# MIMXRT1061 register map
Vendor: nxp.com; File version: 1.0
CPU: CM7 r0p1, little endian, MPU, FPU, VTOR, 4 interrupt priority bits
Registers are 32-bit, read-write, reset 0x0 unless marked. A register's access mark holds for its fields unless they carry their own. Offsets are from the block's base; [hi:lo] are bit positions; {n}, {i} and the like mark numbered series; 'fields as' and 'values as' point back to an identical list.

## GPT1 — GPT
Base 0x401EC000
Same registers: GPT2 0x401F0000
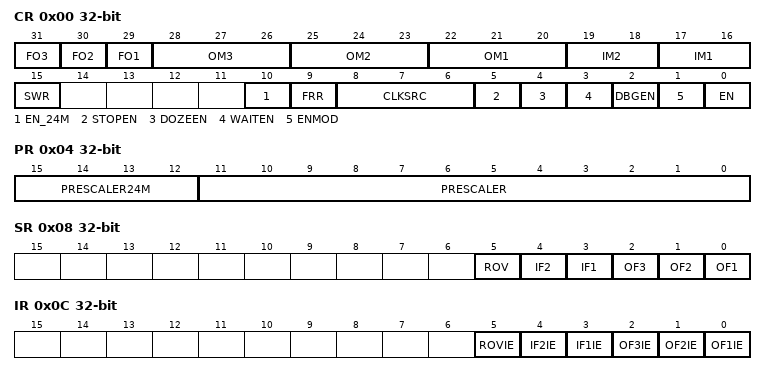
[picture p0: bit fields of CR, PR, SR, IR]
0x00 CR — GPT Control Register
  [31] FO3 — Force Output Compare for Channel 3
    0=NO_FORCE (No effect); 1=FORCE (Trigger the programmed response on the pin)
  [30] FO2 — Force Output Compare for Channel 2
    values as FO3
  [29] FO1 — Force Output Compare for Channel 1
    values as FO3
  [28:26] OM3 — Output Compare Operating Mode for Channel 3
    0=DISABLED (Output disabled. No response on pin.); 1=TOGGLE (Toggle output pin); 2=CLEAR (Clear output pin); 3=SET (Set output pin); 0b1xx=PULSE (Generate a low pulse that is one input clock cycle wide on the output pin. When OMn is first programmed as 1xx, the output pin is set to one immediately on the next input clock (if it was not one already). "Input clock" here refers to the clock selected by the CLKSRC field of this register.)
  [25:23] OM2 — Output Compare Operating Mode for Channel 2
    values as OM3
  [22:20] OM1 — Output Compare Operating Mode for Channel 1
    values as OM3
  [19:18] IM2 — Input Capture Operating Mode for Channel 2
    0=DISABLED (Capture disabled); 1=RISING (Capture on rising edge only); 2=FALLING (Capture on falling edge only); 3=BOTH (Capture on both edges)
  [17:16] IM1 — Input Capture Operating Mode for Channel 1
    values as IM2
  [15] SWR — Software Reset
    0=NOT_SWRESET (GPT is not in software reset state); 1=SWRESET (GPT is in software reset state)
  [10] EN_24M — Enable Oscillator Clock Input
    0=DISABLE; 1=ENABLE
  [9] FRR — Free-Run or Restart Mode
    0=RESTART (Restart mode. After a compare event, the counter resets to 0x0000_0000 and resumes counting.); 1=FREE_RUN (Free-Run mode. After a compare event, the counter continues counting until 0xFFFF_FFFF and then rolls over to 0.)
  [8:6] CLKSRC — Clock Source Select
    0=NO_CLOCK; 1=CLOCK_001 (Peripheral Clock (ipg_clk)); 2=CLOCK_010 (High Frequency Reference Clock (ipg_clk_highfreq)); 3=CLOCK_011 (External Clock); 4=CLOCK_100 (Low Frequency Reference Clock (ipg_clk_32k)); 5=CLOCK_101 (Oscillator as Reference Clock (ipg_clk_24M))
  [5] STOPEN — GPT Stop Mode Enable
    0=STOP_DIS (Disable in Stop mode); 1=STOP_EN (Enable in Stop mode)
  [4] DOZEEN — GPT Doze Mode Enable
    0=DOZE_DIS (Disable in Doze mode); 1=DOZE_EN (Enable in Doze mode)
  [3] WAITEN — GPT Wait Mode Enable
    0=WAIT_DIS (Disable in Wait mode); 1=WAIT_EN (Enable in Wait mode)
  [2] DBGEN — GPT Debug Mode Enable
    0=DEBUG_DIS (Disable in Debug mode); 1=DEBUG_EN (Enable in Debug mode)
  [1] ENMOD — GPT Enable Mode
    0=RESUME_COUNT (Restart counting from their frozen values after GPT is enabled (EN=1).); 1=ZERO_COUNT (Reset counting from 0 after GPT is enabled (EN=1).)
  [0] EN — GPT Enable
    0=DISABLE; 1=ENABLE
0x04 PR — GPT Prescaler Register
  [15:12] PRESCALER24M — Prescaler divide value for the oscillator clock
    0=DIV_BY_1 (Divide by 1); 1=DIV_BY_2 (Divide by 2); 15=DIV_BY_16 (Divide by 16)
  [11:0] PRESCALER — Prescaler divide value
    0=DIV_BY_1 (Divide by 1); 1=DIV_BY_2 (Divide by 2); 0xFFF=DIV_BY_4096 (Divide by 4096)
0x08 SR write-1-clears — GPT Status Register
  [5] ROV write-1-clears — Rollover Flag
    0=NO_ROLLOVER (Rollover has not occurred.); 1=ROLLOVER (Rollover has occurred.)
  [4] IF2 write-1-clears — Input Capture Flag for Channel 2
    0=NO_EVENT (Capture event has not occurred.); 1=EVENT (Capture event has occurred.)
  [3] IF1 write-1-clears — Input Capture Flag for Channel 1
    values as IF2
  [2] OF3 write-1-clears — Output Compare Flag for Channel 3
    0=NO_EVENT (Compare event has not occurred.); 1=EVENT (Compare event has occurred.)
  [1] OF2 write-1-clears — Output Compare Flag for Channel 2
    values as OF3
  [0] OF1 write-1-clears — Output Compare Flag for Channel 1
    values as OF3
0x0C IR — GPT Interrupt Register
  [all] fields
    0=DISABLE; 1=ENABLE
  [5] ROVIE — Rollover Interrupt Enable
  [4] IF2IE — Input Capture Flag for Channel 2 Interrupt Enable
  [3] IF1IE — Input Capture Flag for Channel 1 Interrupt Enable
  [2] OF3IE — Output Compare Flag for Channel 3 Interrupt Enable
  [1] OF2IE — Output Compare Flag for Channel 2 Interrupt Enable
  [0] OF1IE — Output Compare Flag for Channel 1 Interrupt Enable
{0xC+4i} OCR{i} (i=1..3) reset 0xFFFFFFFF — GPT Output Compare Register
  [31:0] COMP — Compare Value
{0x18+4i} ICR{i} (i=1..2) ro — GPT Input Capture Register
  [31:0] CAPT — Capture Value
0x24 CNT ro — GPT Counter Register
  [31:0] COUNT — Counter Value
